VERSION ""

NS_ :

BS_:

BU_:

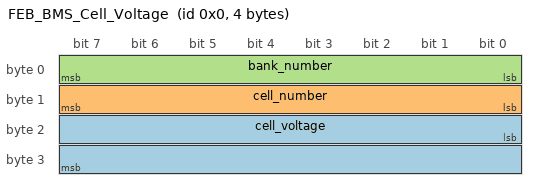
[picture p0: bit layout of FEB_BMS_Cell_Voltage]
BO_ 0 FEB_BMS_Cell_Voltage: 4 Vector__XXX
 SG_ cell_voltage : 16|16@1+ (0.001,0) [0|0] "mV" Vector__XXX
 SG_ cell_number : 8|8@1+ (1,0) [0|0] "" Vector__XXX
 SG_ bank_number : 0|8@1+ (1,0) [0|0] "" Vector__XXX

CM_ BO_ 0 "BMS message for cell voltage.";
